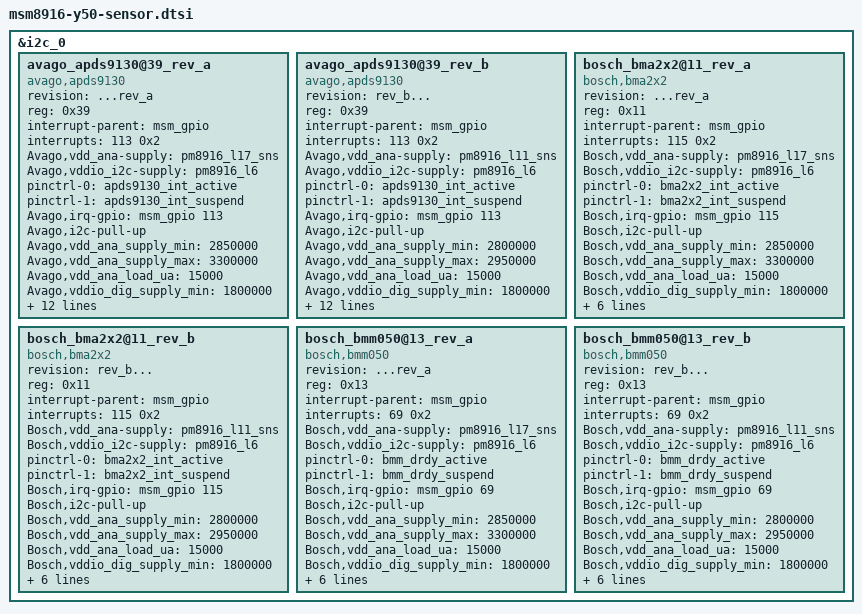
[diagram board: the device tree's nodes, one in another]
/* Copyright (c) 2012, Code Aurora Forum. All rights reserved.
 *
 * This program is free software; you can redistribute it and/or modify
 * it under the terms of the GNU General Public License version 2 and
 * only version 2 as published by the Free Software Foundation.
 *
 * This program is distributed in the hope that it will be useful,
 * but WITHOUT ANY WARRANTY; without even the implied warranty of
 * MERCHANTABILITY or FITNESS FOR A PARTICULAR PURPOSE.  See the
 * GNU General Public License for more details.
 */

&i2c_0{

	/* Proximity sensor */
	avago_apds9130@39_rev_a {
		revision = "...rev_a";
		compatible = "avago,apds9130";
		status ="ok";
		reg = <0x39>;
		interrupt-parent = <&msm_gpio>;
		interrupts = <113 0x2>;
		Avago,vdd_ana-supply = <&pm8916_l17_sns>;
		Avago,vddio_i2c-supply = <&pm8916_l6>;
		pinctrl-names = "default", "sleep";
		pinctrl-0 = <&apds9130_int_active>;
		pinctrl-1 = <&apds9130_int_suspend>;
		Avago,irq-gpio = <&msm_gpio 113 0x0>;
		Avago,i2c-pull-up;
		Avago,vdd_ana_supply_min = <2850000>;
		Avago,vdd_ana_supply_max = <3300000>;
		Avago,vdd_ana_load_ua = <15000>;
		Avago,vddio_dig_supply_min = <1800000>;
		Avago,vddio_dig_supply_max = <1800000>;
		Avago,vddio_dig_load_ua = <10000>;
		Avago,vddio_i2c_supply_min = <1800000>;
		Avago,vddio_i2c_supply_max = <1800000>;
		Avago,vddio_i2c_load_ua = <10000>;
		Avago,ppcount = <8>;
		Avago,pdrive = <0>;
		Avago,near_offset = <300>;
		Avago,far_offset = <100>;
		Avago,crosstalk_max = <720>;
		Avago,bright_threshold = <2000>;
		Avago,dark_threshold = <1000>;
	};

	/* Proximity sensor */
	avago_apds9130@39_rev_b {
		revision = "rev_b...";
		compatible = "avago,apds9130";
		status ="ok";
		reg = <0x39>;
		interrupt-parent = <&msm_gpio>;
		interrupts = <113 0x2>;
		Avago,vdd_ana-supply = <&pm8916_l11_sns>;
		Avago,vddio_i2c-supply = <&pm8916_l6>;
		pinctrl-names = "default", "sleep";
		pinctrl-0 = <&apds9130_int_active>;
		pinctrl-1 = <&apds9130_int_suspend>;
		Avago,irq-gpio = <&msm_gpio 113 0x0>;
		Avago,i2c-pull-up;
		Avago,vdd_ana_supply_min = <2800000>;
		Avago,vdd_ana_supply_max = <2950000>;
		Avago,vdd_ana_load_ua = <15000>;
		Avago,vddio_dig_supply_min = <1800000>;
		Avago,vddio_dig_supply_max = <1800000>;
		Avago,vddio_dig_load_ua = <10000>;
		Avago,vddio_i2c_supply_min = <1800000>;
		Avago,vddio_i2c_supply_max = <1800000>;
		Avago,vddio_i2c_load_ua = <10000>;
		Avago,ppcount = <8>;
		Avago,pdrive = <0>;
		Avago,near_offset = <300>;
		Avago,far_offset = <100>;
		Avago,crosstalk_max = <720>;
		Avago,bright_threshold = <2000>;
		Avago,dark_threshold = <1000>;
	};

	/* Acceleration sensor */
	bosch_bma2x2@11_rev_a {
		revision = "...rev_a";
		compatible = "bosch,bma2x2";
		status = "ok";
		reg = <0x11>;
		interrupt-parent = <&msm_gpio>;
		interrupts = <115 0x2>;
		Bosch,vdd_ana-supply = <&pm8916_l17_sns>;
		Bosch,vddio_i2c-supply = <&pm8916_l6>;
		pinctrl-names = "default", "sleep";
		pinctrl-0 = <&bma2x2_int_active>;
		pinctrl-1 = <&bma2x2_int_suspend>;
		Bosch,irq-gpio = <&msm_gpio 115 0x00>;
		Bosch,i2c-pull-up;
		Bosch,vdd_ana_supply_min = <2850000>;
		Bosch,vdd_ana_supply_max = <3300000>;
		Bosch,vdd_ana_load_ua = <15000>;
		Bosch,vddio_dig_supply_min = <1800000>;
		Bosch,vddio_dig_supply_max = <1800000>;
		Bosch,vddio_dig_load_ua = <10000>;
		Bosch,vddio_i2c_supply_min = <1800000>;
		Bosch,vddio_i2c_supply_max = <1800000>;
		Bosch,vddio_i2c_load_ua = <10000>;
		place = <5>;
	};

	/* Acceleration sensor */
	bosch_bma2x2@11_rev_b {
		revision = "rev_b...";
		compatible = "bosch,bma2x2";
		status = "ok";
		reg = <0x11>;
		interrupt-parent = <&msm_gpio>;
		interrupts = <115 0x2>;
		Bosch,vdd_ana-supply = <&pm8916_l11_sns>;
		Bosch,vddio_i2c-supply = <&pm8916_l6>;
		pinctrl-names = "default", "sleep";
		pinctrl-0 = <&bma2x2_int_active>;
		pinctrl-1 = <&bma2x2_int_suspend>;
		Bosch,irq-gpio = <&msm_gpio 115 0x00>;
		Bosch,i2c-pull-up;
		Bosch,vdd_ana_supply_min = <2800000>;
		Bosch,vdd_ana_supply_max = <2950000>;
		Bosch,vdd_ana_load_ua = <15000>;
		Bosch,vddio_dig_supply_min = <1800000>;
		Bosch,vddio_dig_supply_max = <1800000>;
		Bosch,vddio_dig_load_ua = <10000>;
		Bosch,vddio_i2c_supply_min = <1800000>;
		Bosch,vddio_i2c_supply_max = <1800000>;
		Bosch,vddio_i2c_load_ua = <10000>;
		place = <4>;
	};

	/* Magnetic Sensor Driver */
	bosch_bmm050@13_rev_a {
		revision = "...rev_a";
		compatible = "bosch,bmm050";
		status = "ok";
		reg = <0x13>;
		interrupt-parent = <&msm_gpio>;
		interrupts = <69 0x2>;
		Bosch,vdd_ana-supply = <&pm8916_l17_sns>;
		Bosch,vddio_i2c-supply = <&pm8916_l6>;
		pinctrl-names = "default", "sleep";
		pinctrl-0 = <&bmm_drdy_active>;
		pinctrl-1 = <&bmm_drdy_suspend>;
		Bosch,irq-gpio = <&msm_gpio 69 0x00>;
		Bosch,i2c-pull-up;
		Bosch,vdd_ana_supply_min = <2850000>;
		Bosch,vdd_ana_supply_max = <3300000>;
		Bosch,vdd_ana_load_ua = <15000>;
		Bosch,vddio_dig_supply_min = <1800000>;
		Bosch,vddio_dig_supply_max = <1800000>;
		Bosch,vddio_dig_load_ua = <10000>;
		Bosch,vddio_i2c_supply_min = <1800000>;
		Bosch,vddio_i2c_supply_max = <1800000>;
		Bosch,vddio_i2c_load_ua = <10000>;
		place = <5>;
	};

	/* Magnetic Sensor Driver */
	bosch_bmm050@13_rev_b {
		revision = "rev_b...";
		compatible = "bosch,bmm050";
		status = "ok";
		reg = <0x13>;
		interrupt-parent = <&msm_gpio>;
		interrupts = <69 0x2>;
		Bosch,vdd_ana-supply = <&pm8916_l11_sns>;
		Bosch,vddio_i2c-supply = <&pm8916_l6>;
		pinctrl-names = "default", "sleep";
		pinctrl-0 = <&bmm_drdy_active>;
		pinctrl-1 = <&bmm_drdy_suspend>;
		Bosch,irq-gpio = <&msm_gpio 69 0x00>;
		Bosch,i2c-pull-up;
		Bosch,vdd_ana_supply_min = <2800000>;
		Bosch,vdd_ana_supply_max = <2950000>;
		Bosch,vdd_ana_load_ua = <15000>;
		Bosch,vddio_dig_supply_min = <1800000>;
		Bosch,vddio_dig_supply_max = <1800000>;
		Bosch,vddio_dig_load_ua = <10000>;
		Bosch,vddio_i2c_supply_min = <1800000>;
		Bosch,vddio_i2c_supply_max = <1800000>;
		Bosch,vddio_i2c_load_ua = <10000>;
		place = <4>;
	};
};
